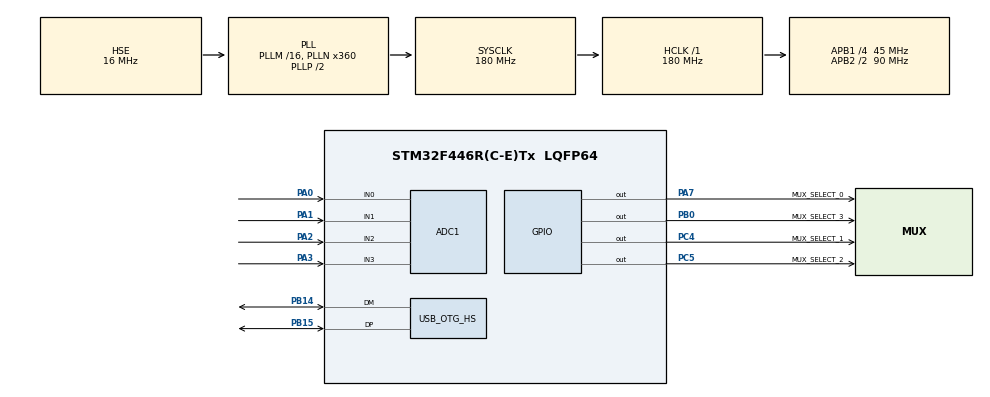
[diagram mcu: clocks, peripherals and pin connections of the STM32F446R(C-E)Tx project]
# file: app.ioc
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ADC1.Channel-0\#ChannelRegularConversion=ADC_CHANNEL_0
ADC1.Channel-1\#ChannelRegularConversion=ADC_CHANNEL_1
ADC1.Channel-2\#ChannelRegularConversion=ADC_CHANNEL_2
ADC1.Channel-3\#ChannelRegularConversion=ADC_CHANNEL_3
ADC1.NbrOfConversion=4
ADC1.NbrOfConversionFlag=1
ADC1.Rank-0\#ChannelRegularConversion=1
ADC1.Rank-1\#ChannelRegularConversion=2
ADC1.Rank-2\#ChannelRegularConversion=3
ADC1.Rank-3\#ChannelRegularConversion=4
ADC1.SamplingTime-0\#ChannelRegularConversion=ADC_SAMPLETIME_3CYCLES
ADC1.SamplingTime-1\#ChannelRegularConversion=ADC_SAMPLETIME_3CYCLES
ADC1.SamplingTime-2\#ChannelRegularConversion=ADC_SAMPLETIME_3CYCLES
ADC1.SamplingTime-3\#ChannelRegularConversion=ADC_SAMPLETIME_3CYCLES
ADC1.master=1
Dma.ADC1.0.Direction=DMA_PERIPH_TO_MEMORY
Dma.ADC1.0.FIFOMode=DMA_FIFOMODE_DISABLE
Dma.ADC1.0.Instance=DMA2_Stream0
Dma.ADC1.0.MemDataAlignment=DMA_MDATAALIGN_HALFWORD
Dma.ADC1.0.MemInc=DMA_MINC_ENABLE
Dma.ADC1.0.Mode=DMA_CIRCULAR
Dma.ADC1.0.PeriphDataAlignment=DMA_PDATAALIGN_HALFWORD
Dma.ADC1.0.PeriphInc=DMA_PINC_DISABLE
Dma.ADC1.0.Priority=DMA_PRIORITY_LOW
Dma.Request0=ADC1
Mcu.Family=STM32F4
Mcu.Name=STM32F446R(C-E)Tx
Mcu.Package=LQFP64
NVIC.ADC_IRQn=true\:0\:0\:false\:false\:true\:true\:true\:true
NVIC.DMA2_Stream0_IRQn=true\:0\:0\:false\:false\:true\:false\:true\:true
NVIC.OTG_HS_IRQn=true\:0\:0\:false\:false\:true\:true\:true\:true
NVIC.PriorityGroup=NVIC_PRIORITYGROUP_4
NVIC.TIM1_UP_TIM10_IRQn=true\:0\:0\:false\:false\:true\:true\:true\:true
PA0-WKUP.Signal=ADCx_IN0
PA1.Signal=ADCx_IN1
PA13.Mode=Trace_Asynchronous_SW
PA13.Signal=SYS_JTMS-SWDIO
PA14.Mode=Trace_Asynchronous_SW
PA14.Signal=SYS_JTCK-SWCLK
PA2.Signal=ADCx_IN2
PA3.Signal=ADCx_IN3
PA7.GPIO_Label=MUX_SELECT_0
PA7.GPIO_Speed=GPIO_SPEED_FREQ_VERY_HIGH
PA7.Signal=GPIO_Output
PB0.GPIO_Label=MUX_SELECT_3
PB0.GPIO_Speed=GPIO_SPEED_FREQ_VERY_HIGH
PB0.Signal=GPIO_Output
PB14.Mode=Device_Only_FS
PB14.Signal=USB_OTG_HS_DM
PB15.Mode=Device_Only_FS
PB15.Signal=USB_OTG_HS_DP
PB3.Mode=Trace_Asynchronous_SW
PB3.Signal=SYS_JTDO-SWO
PC4.GPIO_Label=MUX_SELECT_1
PC4.GPIO_Speed=GPIO_SPEED_FREQ_VERY_HIGH
PC4.Signal=GPIO_Output
PC5.GPIO_Label=MUX_SELECT_2
PC5.GPIO_Speed=GPIO_SPEED_FREQ_VERY_HIGH
PC5.Signal=GPIO_Output
PH0-OSC_IN.Mode=HSE-External-Oscillator
PH0-OSC_IN.Signal=RCC_OSC_IN
PH1-OSC_OUT.Mode=HSE-External-Oscillator
PH1-OSC_OUT.Signal=RCC_OSC_OUT
ProjectManager.HeapSize=0x200
ProjectManager.StackSize=0x400
ProjectManager.TargetToolchain=STM32CubeIDE
RCC.AHBFreq_Value=180000000
RCC.APB1CLKDivider=RCC_HCLK_DIV4
RCC.APB1Freq_Value=45000000
RCC.APB1TimFreq_Value=90000000
RCC.APB2CLKDivider=RCC_HCLK_DIV2
RCC.APB2Freq_Value=90000000
RCC.APB2TimFreq_Value=180000000
RCC.CortexFreq_Value=180000000
RCC.HCLKFreq_Value=180000000
RCC.HSE_VALUE=16000000
RCC.PLLN=360
RCC.PLLSAIP=RCC_PLLSAIP_DIV4
RCC.SYSCLKFreq_VALUE=180000000
RCC.SYSCLKSource=RCC_SYSCLKSOURCE_PLLCLK
RCC.USBCLockSelection=RCC_CLK48CLKSOURCE_PLLSAIP
RCC.USBFreq_Value=48000000
RCC.VCOOutputFreq_Value=360000000
SH.ADCx_IN0.0=ADC1_IN0,IN0
SH.ADCx_IN1.0=ADC1_IN1,IN1
SH.ADCx_IN2.0=ADC1_IN2,IN2
SH.ADCx_IN3.0=ADC1_IN3,IN3
TIM10.Period=1800 - 1
USB_OTG_HS.VirtualMode-Device_Only_FS=Device_Only_FS
VP_TIM10_VS_ClockSourceINT.Mode=Enable_Timer
board=custom

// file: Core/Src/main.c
/* USER CODE BEGIN Header */
/**
 ******************************************************************************
 * @file           : main.c
 * @brief          : Main program body
 ******************************************************************************
 * @attention
 *
 * Copyright (c) 2024 STMicroelectronics.
 * All rights reserved.
 *
 * This software is licensed under terms that can be found in the LICENSE file
 * in the root directory of this software component.
 * If no LICENSE file comes with this software, it is provided AS-IS.
 *
 ******************************************************************************
 */
/* USER CODE END Header */
#include "main.h"

/* USER CODE BEGIN Includes */
#include "app.h"
/* USER CODE END Includes */

ADC_HandleTypeDef hadc1;
DMA_HandleTypeDef hdma_adc1;

TIM_HandleTypeDef htim10;

PCD_HandleTypeDef hpcd_USB_OTG_HS;

void SystemClock_Config(void);
static void MX_GPIO_Init(void);
static void MX_DMA_Init(void);
static void MX_ADC1_Init(void);
static void MX_TIM10_Init(void);
static void MX_USB_OTG_HS_PCD_Init(void);

int main(void) {

    /* MCU
     * Configuration--------------------------------------------------------*/

    /* Reset of all peripherals, Initializes the Flash interface and the
     * Systick. */
    HAL_Init();

    /* Configure the system clock */
    SystemClock_Config();

    /* Initialize all configured peripherals */
    MX_GPIO_Init();
    MX_DMA_Init();
    MX_ADC1_Init();
    MX_TIM10_Init();
    MX_USB_OTG_HS_PCD_Init();
    /* USER CODE BEGIN 2 */
    app_init();
    /* USER CODE END 2 */

    /* Infinite loop */
    /* USER CODE BEGIN WHILE */
    while (1) {
        app_task();
        /* USER CODE END WHILE */

    }
}

void SystemClock_Config(void) {
    RCC_OscInitTypeDef RCC_OscInitStruct = {0};
    RCC_ClkInitTypeDef RCC_ClkInitStruct = {0};

    /** Configure the main internal regulator output voltage
     */
    __HAL_RCC_PWR_CLK_ENABLE();
    __HAL_PWR_VOLTAGESCALING_CONFIG(PWR_REGULATOR_VOLTAGE_SCALE1);

    /** Initializes the RCC Oscillators according to the specified parameters
     * in the RCC_OscInitTypeDef structure.
     */
    RCC_OscInitStruct.OscillatorType = RCC_OSCILLATORTYPE_HSE;
    RCC_OscInitStruct.HSEState = RCC_HSE_ON;
    RCC_OscInitStruct.PLL.PLLState = RCC_PLL_ON;
    RCC_OscInitStruct.PLL.PLLSource = RCC_PLLSOURCE_HSE;
    RCC_OscInitStruct.PLL.PLLM = 16;
    RCC_OscInitStruct.PLL.PLLN = 360;
    RCC_OscInitStruct.PLL.PLLP = RCC_PLLP_DIV2;
    RCC_OscInitStruct.PLL.PLLQ = 2;
    RCC_OscInitStruct.PLL.PLLR = 2;
    if (HAL_RCC_OscConfig(&RCC_OscInitStruct) != HAL_OK) {
        Error_Handler();
    }

    /** Activate the Over-Drive mode
     */
    if (HAL_PWREx_EnableOverDrive() != HAL_OK) {
        Error_Handler();
    }

    /** Initializes the CPU, AHB and APB buses clocks
     */
    RCC_ClkInitStruct.ClockType = RCC_CLOCKTYPE_HCLK | RCC_CLOCKTYPE_SYSCLK |
                                  RCC_CLOCKTYPE_PCLK1 | RCC_CLOCKTYPE_PCLK2;
    RCC_ClkInitStruct.SYSCLKSource = RCC_SYSCLKSOURCE_PLLCLK;
    RCC_ClkInitStruct.AHBCLKDivider = RCC_SYSCLK_DIV1;
    RCC_ClkInitStruct.APB1CLKDivider = RCC_HCLK_DIV4;
    RCC_ClkInitStruct.APB2CLKDivider = RCC_HCLK_DIV2;

    if (HAL_RCC_ClockConfig(&RCC_ClkInitStruct, FLASH_LATENCY_5) != HAL_OK) {
        Error_Handler();
    }
}

static void MX_ADC1_Init(void) {

    ADC_ChannelConfTypeDef sConfig = {0};

    /** Configure the global features of the ADC (Clock, Resolution, Data
     * Alignment and number of conversion)
     */
    hadc1.Instance = ADC1;
    hadc1.Init.ClockPrescaler = ADC_CLOCK_SYNC_PCLK_DIV4;
    hadc1.Init.Resolution = ADC_RESOLUTION_12B;
    hadc1.Init.ScanConvMode = ENABLE;
    hadc1.Init.ContinuousConvMode = DISABLE;
    hadc1.Init.DiscontinuousConvMode = DISABLE;
    hadc1.Init.ExternalTrigConvEdge = ADC_EXTERNALTRIGCONVEDGE_NONE;
    hadc1.Init.ExternalTrigConv = ADC_SOFTWARE_START;
    hadc1.Init.DataAlign = ADC_DATAALIGN_RIGHT;
    hadc1.Init.NbrOfConversion = 4;
    hadc1.Init.DMAContinuousRequests = DISABLE;
    hadc1.Init.EOCSelection = ADC_EOC_SINGLE_CONV;
    if (HAL_ADC_Init(&hadc1) != HAL_OK) {
        Error_Handler();
    }

    /** Configure for the selected ADC regular channel its corresponding rank in
     * the sequencer and its sample time.
     */
    sConfig.Channel = ADC_CHANNEL_0;
    sConfig.Rank = 1;
    sConfig.SamplingTime = ADC_SAMPLETIME_3CYCLES;
    if (HAL_ADC_ConfigChannel(&hadc1, &sConfig) != HAL_OK) {
        Error_Handler();
    }

    /** Configure for the selected ADC regular channel its corresponding rank in
     * the sequencer and its sample time.
     */
    sConfig.Channel = ADC_CHANNEL_1;
    sConfig.Rank = 2;
    if (HAL_ADC_ConfigChannel(&hadc1, &sConfig) != HAL_OK) {
        Error_Handler();
    }

    /** Configure for the selected ADC regular channel its corresponding rank in
     * the sequencer and its sample time.
     */
    sConfig.Channel = ADC_CHANNEL_2;
    sConfig.Rank = 3;
    if (HAL_ADC_ConfigChannel(&hadc1, &sConfig) != HAL_OK) {
        Error_Handler();
    }

    /** Configure for the selected ADC regular channel its corresponding rank in
     * the sequencer and its sample time.
     */
    sConfig.Channel = ADC_CHANNEL_3;
    sConfig.Rank = 4;
    if (HAL_ADC_ConfigChannel(&hadc1, &sConfig) != HAL_OK) {
        Error_Handler();
    }
}

static void MX_TIM10_Init(void) {

    htim10.Instance = TIM10;
    htim10.Init.Prescaler = 0;
    htim10.Init.CounterMode = TIM_COUNTERMODE_UP;
    htim10.Init.Period = 1800 - 1;
    htim10.Init.ClockDivision = TIM_CLOCKDIVISION_DIV1;
    htim10.Init.AutoReloadPreload = TIM_AUTORELOAD_PRELOAD_DISABLE;
    if (HAL_TIM_Base_Init(&htim10) != HAL_OK) {
        Error_Handler();
    }
}

static void MX_USB_OTG_HS_PCD_Init(void) {

    hpcd_USB_OTG_HS.Instance = USB_OTG_HS;
    hpcd_USB_OTG_HS.Init.dev_endpoints = 8;
    hpcd_USB_OTG_HS.Init.speed = PCD_SPEED_FULL;
    hpcd_USB_OTG_HS.Init.dma_enable = DISABLE;
    hpcd_USB_OTG_HS.Init.phy_itface = USB_OTG_EMBEDDED_PHY;
    hpcd_USB_OTG_HS.Init.Sof_enable = DISABLE;
    hpcd_USB_OTG_HS.Init.low_power_enable = DISABLE;
    hpcd_USB_OTG_HS.Init.lpm_enable = DISABLE;
    hpcd_USB_OTG_HS.Init.vbus_sensing_enable = DISABLE;
    hpcd_USB_OTG_HS.Init.use_dedicated_ep1 = DISABLE;
    hpcd_USB_OTG_HS.Init.use_external_vbus = DISABLE;
    if (HAL_PCD_Init(&hpcd_USB_OTG_HS) != HAL_OK) {
        Error_Handler();
    }
}

static void MX_DMA_Init(void) {

    /* DMA controller clock enable */
    __HAL_RCC_DMA2_CLK_ENABLE();

    /* DMA interrupt init */
    /* DMA2_Stream0_IRQn interrupt configuration */
    HAL_NVIC_SetPriority(DMA2_Stream0_IRQn, 0, 0);
    HAL_NVIC_EnableIRQ(DMA2_Stream0_IRQn);
}

static void MX_GPIO_Init(void) {
    GPIO_InitTypeDef GPIO_InitStruct = {0};

    /* GPIO Ports Clock Enable */
    __HAL_RCC_GPIOH_CLK_ENABLE();
    __HAL_RCC_GPIOA_CLK_ENABLE();
    __HAL_RCC_GPIOC_CLK_ENABLE();
    __HAL_RCC_GPIOB_CLK_ENABLE();

    /*Configure GPIO pin Output Level */
    HAL_GPIO_WritePin(MUX_SELECT_0_GPIO_Port, MUX_SELECT_0_Pin, GPIO_PIN_RESET);

    /*Configure GPIO pin Output Level */
    HAL_GPIO_WritePin(GPIOC, MUX_SELECT_1_Pin | MUX_SELECT_2_Pin,
                      GPIO_PIN_RESET);

    /*Configure GPIO pin Output Level */
    HAL_GPIO_WritePin(MUX_SELECT_3_GPIO_Port, MUX_SELECT_3_Pin, GPIO_PIN_RESET);

    /*Configure GPIO pin : MUX_SELECT_0_Pin */
    GPIO_InitStruct.Pin = MUX_SELECT_0_Pin;
    GPIO_InitStruct.Mode = GPIO_MODE_OUTPUT_PP;
    GPIO_InitStruct.Pull = GPIO_NOPULL;
    GPIO_InitStruct.Speed = GPIO_SPEED_FREQ_VERY_HIGH;
    HAL_GPIO_Init(MUX_SELECT_0_GPIO_Port, &GPIO_InitStruct);

    /*Configure GPIO pins : MUX_SELECT_1_Pin MUX_SELECT_2_Pin */
    GPIO_InitStruct.Pin = MUX_SELECT_1_Pin | MUX_SELECT_2_Pin;
    GPIO_InitStruct.Mode = GPIO_MODE_OUTPUT_PP;
    GPIO_InitStruct.Pull = GPIO_NOPULL;
    GPIO_InitStruct.Speed = GPIO_SPEED_FREQ_VERY_HIGH;
    HAL_GPIO_Init(GPIOC, &GPIO_InitStruct);

    /*Configure GPIO pin : MUX_SELECT_3_Pin */
    GPIO_InitStruct.Pin = MUX_SELECT_3_Pin;
    GPIO_InitStruct.Mode = GPIO_MODE_OUTPUT_PP;
    GPIO_InitStruct.Pull = GPIO_NOPULL;
    GPIO_InitStruct.Speed = GPIO_SPEED_FREQ_VERY_HIGH;
    HAL_GPIO_Init(MUX_SELECT_3_GPIO_Port, &GPIO_InitStruct);

}

void Error_Handler(void) {
    /* USER CODE BEGIN Error_Handler_Debug */
    /* User can add his own implementation to report the HAL error return state
     */
    __disable_irq();
    while (1) {
    }
    /* USER CODE END Error_Handler_Debug */
}

#ifdef USE_FULL_ASSERT
/**
 * @brief  Reports the name of the source file and the source line number
 *         where the assert_param error has occurred.
 * @param  file: pointer to the source file name
 * @param  line: assert_param error line source number
 * @retval None
 */
void assert_failed(uint8_t *file, uint32_t line) {
    /* USER CODE BEGIN 6 */
    /* User can add his own implementation to report the file name and line
       number, ex: printf("Wrong parameters value: file %s on line %d\r\n",
       file, line) */
    /* USER CODE END 6 */
}
#endif /* USE_FULL_ASSERT */
